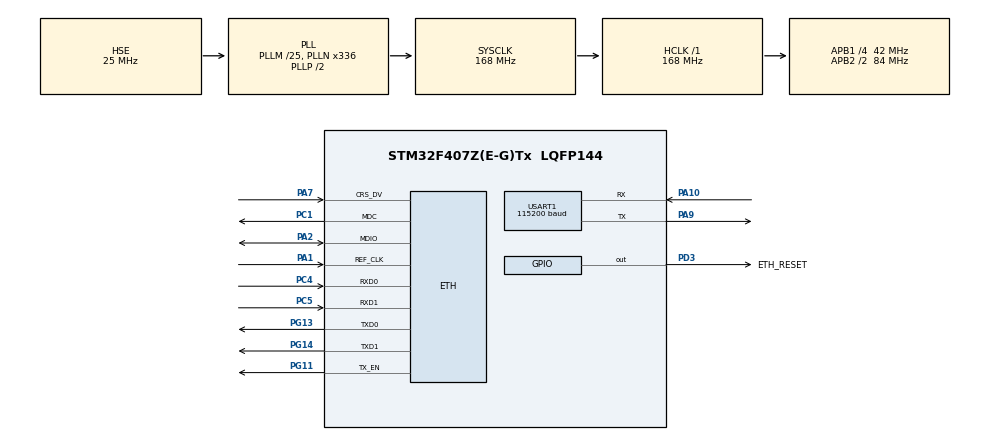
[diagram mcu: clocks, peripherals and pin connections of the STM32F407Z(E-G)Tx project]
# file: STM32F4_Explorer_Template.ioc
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ETH.MediaInterface=HAL_ETH_RMII_MODE
Mcu.Family=STM32F4
Mcu.Name=STM32F407Z(E-G)Tx
Mcu.Package=LQFP144
NVIC.ETH_IRQn=true\:0\:0\:false\:false\:false\:true\:true\:true
NVIC.PriorityGroup=NVIC_PRIORITYGROUP_4
NVIC.USART1_IRQn=true\:10\:0\:true\:false\:false\:true\:true\:true
PA1.Mode=RMII
PA1.Signal=ETH_REF_CLK
PA10.Mode=Asynchronous
PA10.Signal=USART1_RX
PA13.Mode=Serial_Wire
PA13.Signal=SYS_JTMS-SWDIO
PA14.Mode=Serial_Wire
PA14.Signal=SYS_JTCK-SWCLK
PA2.Mode=RMII
PA2.Signal=ETH_MDIO
PA7.Mode=RMII
PA7.Signal=ETH_CRS_DV
PA9.Mode=Asynchronous
PA9.Signal=USART1_TX
PC1.Mode=RMII
PC1.Signal=ETH_MDC
PC4.Mode=RMII
PC4.Signal=ETH_RXD0
PC5.Mode=RMII
PC5.Signal=ETH_RXD1
PD3.GPIO_Label=ETH_RESET
PD3.GPIO_ModeDefaultOutputPP=GPIO_MODE_OUTPUT_PP
PD3.GPIO_Speed=GPIO_SPEED_FREQ_VERY_HIGH
PD3.PinState=GPIO_PIN_RESET
PD3.Signal=GPIO_Output
PG11.Mode=RMII
PG11.Signal=ETH_TX_EN
PG13.Mode=RMII
PG13.Signal=ETH_TXD0
PG14.Mode=RMII
PG14.Signal=ETH_TXD1
PH0-OSC_IN.Mode=HSE-External-Oscillator
PH0-OSC_IN.Signal=RCC_OSC_IN
PH1-OSC_OUT.Mode=HSE-External-Oscillator
PH1-OSC_OUT.Signal=RCC_OSC_OUT
ProjectManager.HeapSize=0x200
ProjectManager.StackSize=0x400
ProjectManager.TargetToolchain=MDK-ARM V5.32
RCC.48MHZClocksFreq_Value=84000000
RCC.AHBFreq_Value=168000000
RCC.APB1CLKDivider=RCC_HCLK_DIV4
RCC.APB1Freq_Value=42000000
RCC.APB1TimFreq_Value=84000000
RCC.APB2CLKDivider=RCC_HCLK_DIV2
RCC.APB2Freq_Value=84000000
RCC.APB2TimFreq_Value=168000000
RCC.CortexFreq_Value=168000000
RCC.HCLKFreq_Value=168000000
RCC.HSE_VALUE=25000000
RCC.HSI_VALUE=16000000
RCC.LSE_VALUE=32768
RCC.PLLM=25
RCC.PLLN=336
RCC.PLLSourceVirtual=RCC_PLLSOURCE_HSE
RCC.SYSCLKFreq_VALUE=168000000
RCC.SYSCLKSource=RCC_SYSCLKSOURCE_PLLCLK
RCC.VCOOutputFreq_Value=336000000
USART1.BaudRate=115200
USART1.VirtualMode=VM_ASYNC
board=custom

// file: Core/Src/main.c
/* USER CODE BEGIN Header */
/**
  ******************************************************************************
  * @file           : main.c
  * @brief          : Main program body
  ******************************************************************************
  * @attention
  *
  * Copyright (c) 2024 STMicroelectronics.
  * All rights reserved.
  *
  * This software is licensed under terms that can be found in the LICENSE file
  * in the root directory of this software component.
  * If no LICENSE file comes with this software, it is provided AS-IS.
  *
  ******************************************************************************
  */
/* USER CODE END Header */
#include "main.h"
#include "string.h"

/* USER CODE BEGIN Includes */
#include "system.h"
#include "task_run.h"
/* USER CODE END Includes */

/* USER CODE BEGIN PM */
#if 0
/* USER CODE END PM */

ETH_TxPacketConfig TxConfig;
ETH_DMADescTypeDef  DMARxDscrTab[ETH_RX_DESC_CNT]; /* Ethernet Rx DMA Descriptors */
ETH_DMADescTypeDef  DMATxDscrTab[ETH_TX_DESC_CNT]; /* Ethernet Tx DMA Descriptors */

UART_HandleTypeDef huart1;

/* USER CODE BEGIN PV */
#endif
UART_HandleTypeDef huart1;
/* USER CODE END PV */

void SystemClock_Config(void);
static void MX_GPIO_Init(void);
static void MX_USART1_UART_Init(void);

int main(void)
{

  /* MCU Configuration--------------------------------------------------------*/

  /* Reset of all peripherals, Initializes the Flash interface and the Systick. */
  HAL_Init();

  /* Configure the system clock */
  SystemClock_Config();

  /* Initialize all configured peripherals */
  MX_GPIO_Init();
  MX_USART1_UART_Init();
  /* USER CODE BEGIN 2 */
  system_init();
  /* USER CODE END 2 */

  /* Infinite loop */
  /* USER CODE BEGIN WHILE */
  while (1)
  {
    task_process();
    /* USER CODE END WHILE */

  }
}

void SystemClock_Config(void)
{
  RCC_OscInitTypeDef RCC_OscInitStruct = {0};
  RCC_ClkInitTypeDef RCC_ClkInitStruct = {0};

  /** Configure the main internal regulator output voltage
  */
  __HAL_RCC_PWR_CLK_ENABLE();
  __HAL_PWR_VOLTAGESCALING_CONFIG(PWR_REGULATOR_VOLTAGE_SCALE1);

  /** Initializes the RCC Oscillators according to the specified parameters
  * in the RCC_OscInitTypeDef structure.
  */
  RCC_OscInitStruct.OscillatorType = RCC_OSCILLATORTYPE_HSE;
  RCC_OscInitStruct.HSEState = RCC_HSE_ON;
  RCC_OscInitStruct.PLL.PLLState = RCC_PLL_ON;
  RCC_OscInitStruct.PLL.PLLSource = RCC_PLLSOURCE_HSE;
  RCC_OscInitStruct.PLL.PLLM = 25;
  RCC_OscInitStruct.PLL.PLLN = 336;
  RCC_OscInitStruct.PLL.PLLP = RCC_PLLP_DIV2;
  RCC_OscInitStruct.PLL.PLLQ = 4;
  if (HAL_RCC_OscConfig(&RCC_OscInitStruct) != HAL_OK)
  {
    Error_Handler();
  }

  /** Initializes the CPU, AHB and APB buses clocks
  */
  RCC_ClkInitStruct.ClockType = RCC_CLOCKTYPE_HCLK|RCC_CLOCKTYPE_SYSCLK
                              |RCC_CLOCKTYPE_PCLK1|RCC_CLOCKTYPE_PCLK2;
  RCC_ClkInitStruct.SYSCLKSource = RCC_SYSCLKSOURCE_PLLCLK;
  RCC_ClkInitStruct.AHBCLKDivider = RCC_SYSCLK_DIV1;
  RCC_ClkInitStruct.APB1CLKDivider = RCC_HCLK_DIV4;
  RCC_ClkInitStruct.APB2CLKDivider = RCC_HCLK_DIV2;

  if (HAL_RCC_ClockConfig(&RCC_ClkInitStruct, FLASH_LATENCY_5) != HAL_OK)
  {
    Error_Handler();
  }
}

static void MX_USART1_UART_Init(void)
{

  huart1.Instance = USART1;
  huart1.Init.BaudRate = 115200;
  huart1.Init.WordLength = UART_WORDLENGTH_8B;
  huart1.Init.StopBits = UART_STOPBITS_1;
  huart1.Init.Parity = UART_PARITY_NONE;
  huart1.Init.Mode = UART_MODE_TX_RX;
  huart1.Init.HwFlowCtl = UART_HWCONTROL_NONE;
  huart1.Init.OverSampling = UART_OVERSAMPLING_16;
  if (HAL_UART_Init(&huart1) != HAL_OK)
  {
    Error_Handler();
  }

}

static void MX_GPIO_Init(void)
{
  GPIO_InitTypeDef GPIO_InitStruct = {0};

  /* GPIO Ports Clock Enable */
  __HAL_RCC_GPIOH_CLK_ENABLE();
  __HAL_RCC_GPIOC_CLK_ENABLE();
  __HAL_RCC_GPIOA_CLK_ENABLE();
  __HAL_RCC_GPIOD_CLK_ENABLE();
  __HAL_RCC_GPIOG_CLK_ENABLE();

  /*Configure GPIO pin Output Level */
  HAL_GPIO_WritePin(ETH_RESET_GPIO_Port, ETH_RESET_Pin, GPIO_PIN_RESET);

  /*Configure GPIO pin : ETH_RESET_Pin */
  GPIO_InitStruct.Pin = ETH_RESET_Pin;
  GPIO_InitStruct.Mode = GPIO_MODE_OUTPUT_PP;
  GPIO_InitStruct.Pull = GPIO_NOPULL;
  GPIO_InitStruct.Speed = GPIO_SPEED_FREQ_VERY_HIGH;
  HAL_GPIO_Init(ETH_RESET_GPIO_Port, &GPIO_InitStruct);

}

void Error_Handler(void)
{
  __disable_irq();
  while (1)
  {
  }
}
